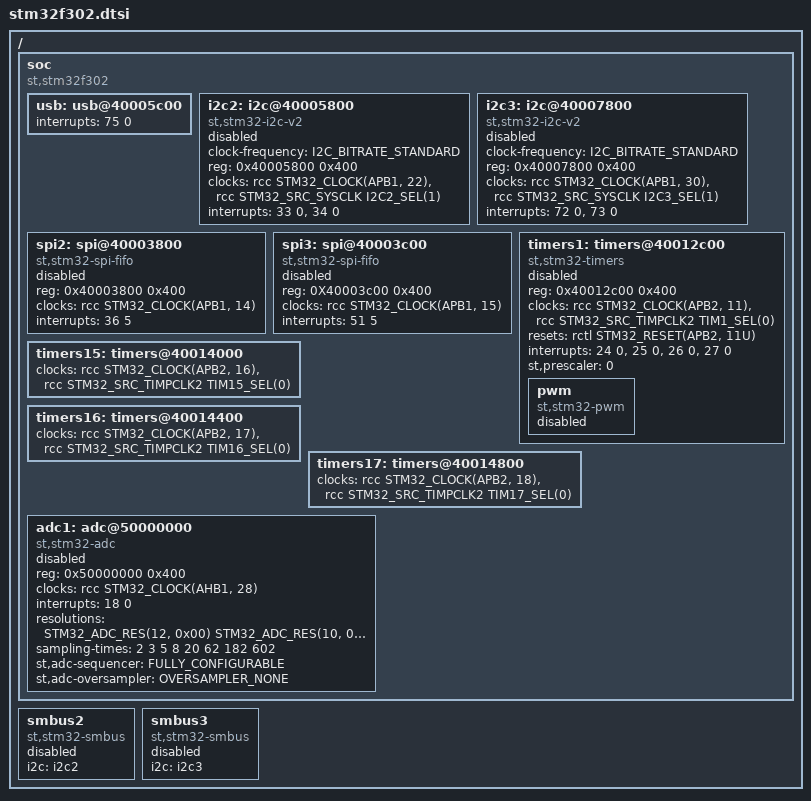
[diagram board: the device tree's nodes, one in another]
/*
 * Copyright (c) 2018 Seitz & Associates
 *
 * SPDX-License-Identifier: Apache-2.0
 */

#include <st/f3/stm32f3.dtsi>
#include <zephyr/dt-bindings/adc/stm32l4_adc.h>

/ {
	soc {
		compatible = "st,stm32f302", "st,stm32f3", "simple-bus";

		usb: usb@40005c00 {
			/* Remap USB_LP IRQ to enable use with CAN_1 */
			interrupts = <75 0>;
		};

		i2c2: i2c@40005800 {
			compatible = "st,stm32-i2c-v2";
			clock-frequency = <I2C_BITRATE_STANDARD>;
			#address-cells = <1>;
			#size-cells = <0>;
			reg = <0x40005800 0x400>;
			clocks = <&rcc STM32_CLOCK(APB1, 22)>,
				 /* I2C clock source should always be defined,
				  * even for the default value
				  */
				 <&rcc STM32_SRC_SYSCLK I2C2_SEL(1)>;
			interrupts = <33 0>, <34 0>;
			interrupt-names = "event", "error";
			status = "disabled";
		};

		i2c3: i2c@40007800 {
			compatible = "st,stm32-i2c-v2";
			clock-frequency = <I2C_BITRATE_STANDARD>;
			#address-cells = <1>;
			#size-cells = <0>;
			reg = <0x40007800 0x400>;
			clocks = <&rcc STM32_CLOCK(APB1, 30)>,
				 /* I2C clock source should always be defined,
				  * even for the default value
				  */
				 <&rcc STM32_SRC_SYSCLK I2C3_SEL(1)>;
			interrupts = <72 0>, <73 0>;
			interrupt-names = "event", "error";
			status = "disabled";
		};

		spi2: spi@40003800 {
			compatible = "st,stm32-spi-fifo", "st,stm32-spi";
			#address-cells = <1>;
			#size-cells = <0>;
			reg = <0x40003800 0x400>;
			clocks = <&rcc STM32_CLOCK(APB1, 14)>;
			interrupts = <36 5>;
			status = "disabled";
		};

		spi3: spi@40003c00 {
			compatible = "st,stm32-spi-fifo", "st,stm32-spi";
			#address-cells = <1>;
			#size-cells = <0>;
			reg = <0X40003c00 0x400>;
			clocks = <&rcc STM32_CLOCK(APB1, 15)>;
			interrupts = <51 5>;
			status = "disabled";
		};

		timers1: timers@40012c00 {
			compatible = "st,stm32-timers";
			reg = <0x40012c00 0x400>;
			clocks = <&rcc STM32_CLOCK(APB2, 11)>,
				 <&rcc STM32_SRC_TIMPCLK2 TIM1_SEL(0)>;
			resets = <&rctl STM32_RESET(APB2, 11U)>;
			interrupts = <24 0>, <25 0>, <26 0>, <27 0>;
			interrupt-names = "brk", "up", "trgcom", "cc";
			st,prescaler = <0>;
			status = "disabled";

			pwm {
				compatible = "st,stm32-pwm";
				status = "disabled";
				#pwm-cells = <3>;
			};
		};

		timers15: timers@40014000 {
			clocks = <&rcc STM32_CLOCK(APB2, 16)>,
				 <&rcc STM32_SRC_TIMPCLK2 TIM15_SEL(0)>;
		};

		timers16: timers@40014400 {
			clocks = <&rcc STM32_CLOCK(APB2, 17)>,
				 <&rcc STM32_SRC_TIMPCLK2 TIM16_SEL(0)>;
		};

		timers17: timers@40014800 {
			clocks = <&rcc STM32_CLOCK(APB2, 18)>,
				 <&rcc STM32_SRC_TIMPCLK2 TIM17_SEL(0)>;
		};

		adc1: adc@50000000 {
			compatible = "st,stm32-adc";
			reg = <0x50000000 0x400>;
			clocks = <&rcc STM32_CLOCK(AHB1, 28)>;
			interrupts = <18 0>;
			status = "disabled";
			#io-channel-cells = <1>;
			resolutions = <STM32_ADC_RES(12, 0x00)
				       STM32_ADC_RES(10, 0x01)
				       STM32_ADC_RES(8, 0x02)
				       STM32_ADC_RES(6, 0x03)>;
			sampling-times = <2 3 5 8 20 62 182 602>;
			st,adc-sequencer = "FULLY_CONFIGURABLE";
			st,adc-oversampler = "OVERSAMPLER_NONE";
		};
	};

	smbus2: smbus2 {
		compatible = "st,stm32-smbus";
		#address-cells = <1>;
		#size-cells = <0>;
		i2c = <&i2c2>;
		status = "disabled";
	};

	smbus3: smbus3 {
		compatible = "st,stm32-smbus";
		#address-cells = <1>;
		#size-cells = <0>;
		i2c = <&i2c3>;
		status = "disabled";
	};
};
